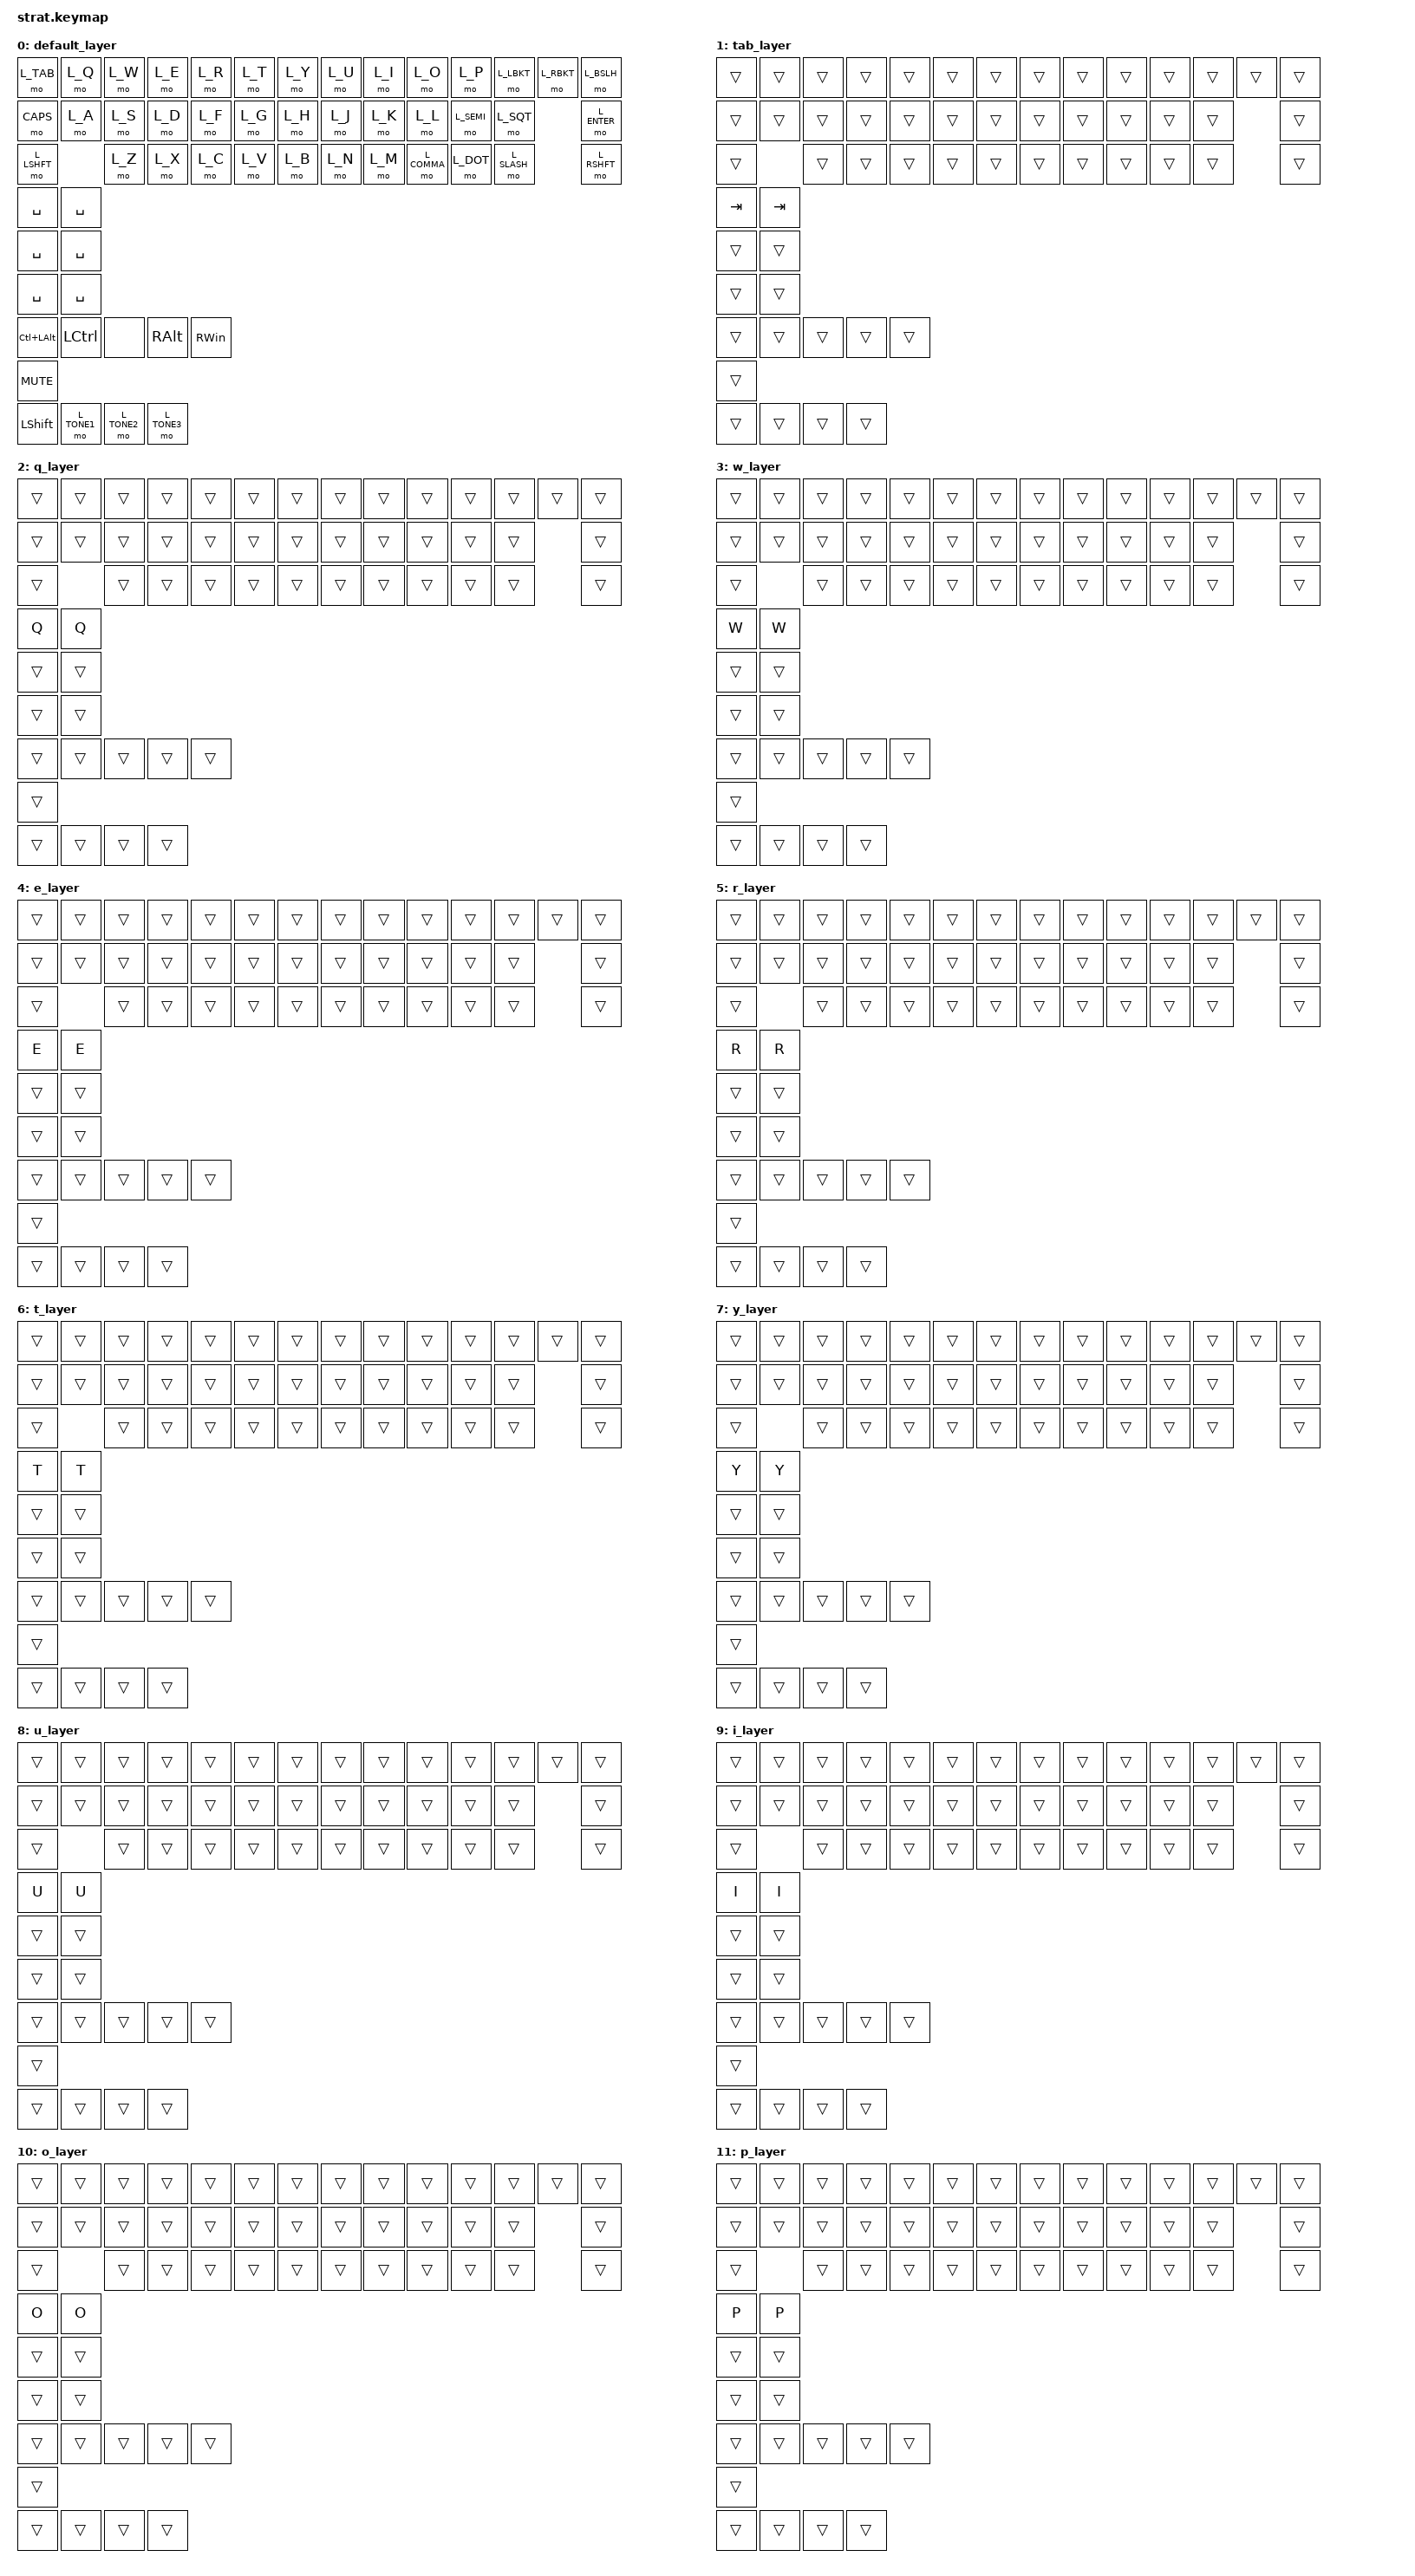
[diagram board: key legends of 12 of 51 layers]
#include <behaviors.dtsi>
#include <dt-bindings/zmk/keys.h>
#include <dt-bindings/zmk/bt.h>

#define DEFAULT    0

#define L_TAB     1
#define L_Q       2
#define L_W       3
#define L_E       4
#define L_R       5
#define L_T       6
#define L_Y       7
#define L_U       8
#define L_I       9
#define L_O       10
#define L_P       11
#define L_LBKT    12
#define L_RBKT    13
#define L_BSLH    14

#define L_CAPS    15
#define L_A       16
#define L_S       17
#define L_D       18
#define L_F       19
#define L_G       20
#define L_H       21
#define L_J       22
#define L_K       23
#define L_L       24
#define L_SEMI    25
#define L_SQT     26
#define L_ENTER   27

#define L_LSHFT   28
#define L_Z       29
#define L_X       30
#define L_C       31
#define L_V       32
#define L_B       33
#define L_N       34
#define L_M       35
#define L_COMMA   36
#define L_DOT     37
#define L_SLASH   38
#define L_RSHFT   39

#define L_PU0     40
#define L_PU1     41
#define L_PU2     42
#define L_PU3     43
#define L_PU4     44
#define L_TAB     45

#define L_TONE0   46
#define L_TONE1   47
#define L_TONE2   48
#define L_TONE3   49

#define L_CONFIG  50
#define L_NORMAL  51

/ {
    keymap {
        compatible = "zmk,keymap";

        // LAYER 0
        default_layer {
            bindings = <
                &mo L_TAB    &mo L_Q      &mo L_W      &mo L_E      &mo L_R      &mo L_T      &mo L_Y      &mo L_U      &mo L_I      &mo L_O      &mo L_P      &mo L_LBKT   &mo L_RBKT   &mo L_BSLH
                &mo CAPS     &mo L_A      &mo L_S      &mo L_D      &mo L_F      &mo L_G      &mo L_H      &mo L_J      &mo L_K      &mo L_L      &mo L_SEMI   &mo L_SQT                 &mo L_ENTER
                &mo L_LSHFT               &mo L_Z      &mo L_X      &mo L_C      &mo L_V      &mo L_B      &mo L_N      &mo L_M      &mo L_COMMA  &mo L_DOT    &mo L_SLASH               &mo L_RSHFT

                &kp SPACE    &kp SPACE
                &kp SPACE    &kp SPACE
                &kp SPACE    &kp SPACE

                &kp LC(LALT) &kp LCTRL    &none        &kp RALT     &kp RWIN
                &kp C_MUTE
                &kp LSHIFT   &mo L_TONE1  &mo L_TONE2  &mo L_TONE3
            >;
        };

        tab_layer {
            bindings = <
                &trans &trans &trans &trans &trans &trans &trans &trans &trans &trans &trans &trans &trans &trans &trans &trans &trans &trans &trans &trans &trans &trans &trans &trans &trans &trans &trans &trans &trans &trans &trans &trans &trans &trans &trans &trans &trans &trans &trans

                &kp TAB &kp TAB
                &trans &trans
                &trans &trans

                &trans &trans &trans &trans &trans &trans &trans &trans &trans &trans
            >;
        };

        q_layer {
            bindings = <
                &trans &trans &trans &trans &trans &trans &trans &trans &trans &trans &trans &trans &trans &trans &trans &trans &trans &trans &trans &trans &trans &trans &trans &trans &trans &trans &trans &trans &trans &trans &trans &trans &trans &trans &trans &trans &trans &trans &trans

                &kp Q &kp Q
                &trans &trans
                &trans &trans

                &trans &trans &trans &trans &trans &trans &trans &trans &trans &trans
            >;
        };

        w_layer {
            bindings = <
                &trans &trans &trans &trans &trans &trans &trans &trans &trans &trans &trans &trans &trans &trans &trans &trans &trans &trans &trans &trans &trans &trans &trans &trans &trans &trans &trans &trans &trans &trans &trans &trans &trans &trans &trans &trans &trans &trans &trans

                &kp W &kp W
                &trans &trans
                &trans &trans

                &trans &trans &trans &trans &trans &trans &trans &trans &trans &trans
            >;
        };

        e_layer {
            bindings = <
                &trans &trans &trans &trans &trans &trans &trans &trans &trans &trans &trans &trans &trans &trans &trans &trans &trans &trans &trans &trans &trans &trans &trans &trans &trans &trans &trans &trans &trans &trans &trans &trans &trans &trans &trans &trans &trans &trans &trans

                &kp E &kp E
                &trans &trans
                &trans &trans

                &trans &trans &trans &trans &trans &trans &trans &trans &trans &trans
            >;
        };

        r_layer {
            bindings = <
                &trans &trans &trans &trans &trans &trans &trans &trans &trans &trans &trans &trans &trans &trans &trans &trans &trans &trans &trans &trans &trans &trans &trans &trans &trans &trans &trans &trans &trans &trans &trans &trans &trans &trans &trans &trans &trans &trans &trans

                &kp R &kp R
                &trans &trans
                &trans &trans

                &trans &trans &trans &trans &trans &trans &trans &trans &trans &trans
            >;
        };

        t_layer {
            bindings = <
                &trans &trans &trans &trans &trans &trans &trans &trans &trans &trans &trans &trans &trans &trans &trans &trans &trans &trans &trans &trans &trans &trans &trans &trans &trans &trans &trans &trans &trans &trans &trans &trans &trans &trans &trans &trans &trans &trans &trans

                &kp T &kp T
                &trans &trans
                &trans &trans

                &trans &trans &trans &trans &trans &trans &trans &trans &trans &trans
            >;
        };

        y_layer {
            bindings = <
                &trans &trans &trans &trans &trans &trans &trans &trans &trans &trans &trans &trans &trans &trans &trans &trans &trans &trans &trans &trans &trans &trans &trans &trans &trans &trans &trans &trans &trans &trans &trans &trans &trans &trans &trans &trans &trans &trans &trans

                &kp Y &kp Y
                &trans &trans
                &trans &trans

                &trans &trans &trans &trans &trans &trans &trans &trans &trans &trans
            >;
        };

        u_layer {
            bindings = <
                &trans &trans &trans &trans &trans &trans &trans &trans &trans &trans &trans &trans &trans &trans &trans &trans &trans &trans &trans &trans &trans &trans &trans &trans &trans &trans &trans &trans &trans &trans &trans &trans &trans &trans &trans &trans &trans &trans &trans

                &kp U &kp U
                &trans &trans
                &trans &trans

                &trans &trans &trans &trans &trans &trans &trans &trans &trans &trans
            >;
        };

        i_layer {
            bindings = <
                &trans &trans &trans &trans &trans &trans &trans &trans &trans &trans &trans &trans &trans &trans &trans &trans &trans &trans &trans &trans &trans &trans &trans &trans &trans &trans &trans &trans &trans &trans &trans &trans &trans &trans &trans &trans &trans &trans &trans

                &kp I &kp I
                &trans &trans
                &trans &trans

                &trans &trans &trans &trans &trans &trans &trans &trans &trans &trans
            >;
        };

        // LAYER 10
        o_layer {
            bindings = <
                &trans &trans &trans &trans &trans &trans &trans &trans &trans &trans &trans &trans &trans &trans &trans &trans &trans &trans &trans &trans &trans &trans &trans &trans &trans &trans &trans &trans &trans &trans &trans &trans &trans &trans &trans &trans &trans &trans &trans

                &kp O &kp O
                &trans &trans
                &trans &trans

                &trans &trans &trans &trans &trans &trans &trans &trans &trans &trans
            >;
        };

        p_layer {
            bindings = <
                &trans &trans &trans &trans &trans &trans &trans &trans &trans &trans &trans &trans &trans &trans &trans &trans &trans &trans &trans &trans &trans &trans &trans &trans &trans &trans &trans &trans &trans &trans &trans &trans &trans &trans &trans &trans &trans &trans &trans

                &kp P &kp P
                &trans &trans
                &trans &trans

                &trans &trans &trans &trans &trans &trans &trans &trans &trans &trans
            >;
        };

        lbkt_layer {
            bindings = <
                &trans &trans &trans &trans &trans &trans &trans &trans &trans &trans &trans &trans &trans &trans &trans &trans &trans &trans &trans &trans &trans &trans &trans &trans &trans &trans &trans &trans &trans &trans &trans &trans &trans &trans &trans &trans &trans &trans &trans

                &kp LBKT &kp LBKT
                &trans &trans
                &trans &trans

                &trans &trans &trans &trans &trans &trans &trans &trans &trans &trans
            >;
        };

        rbkt_layer {
            bindings = <
                &trans &trans &trans &trans &trans &trans &trans &trans &trans &trans &trans &trans &trans &trans &trans &trans &trans &trans &trans &trans &trans &trans &trans &trans &trans &trans &trans &trans &trans &trans &trans &trans &trans &trans &trans &trans &trans &trans &trans

                &kp RBKT &kp RBKT
                &trans &trans
                &trans &trans

                &trans &trans &trans &trans &trans &trans &trans &trans &trans &trans
            >;
        };

        bslh_layer {
            bindings = <
                &trans &trans &trans &trans &trans &trans &trans &trans &trans &trans &trans &trans &trans &trans &trans &trans &trans &trans &trans &trans &trans &trans &trans &trans &trans &trans &trans &trans &trans &trans &trans &trans &trans &trans &trans &trans &trans &trans &trans

                &kp BSLH &kp BSLH
                &trans &trans
                &trans &trans

                &trans &trans &trans &trans &trans &trans &trans &trans &trans &trans
            >;
        };

        caps_layer {
            bindings = <
                &trans &trans &trans &trans &trans &trans &trans &trans &trans &trans &trans &trans &trans &trans &trans &trans &trans &trans &trans &trans &trans &trans &trans &trans &trans &trans &trans &trans &trans &trans &trans &trans &trans &trans &trans &trans &trans &trans &trans

                &trans &trans
                &kp CAPS &kp CAPS
                &trans &trans

                &trans &trans &trans &trans &trans &trans &trans &trans &trans &trans
            >;
        };

        a_layer {
            bindings = <
                &trans &trans &trans &trans &trans &trans &trans &trans &trans &trans &trans &trans &trans &trans &trans &trans &trans &trans &trans &trans &trans &trans &trans &trans &trans &trans &trans &trans &trans &trans &trans &trans &trans &trans &trans &trans &trans &trans &trans

                &trans &trans
                &kp A &kp A
                &trans &trans

                &trans &trans &trans &trans &trans &trans &trans &trans &trans &trans
            >;
        };

        s_layer {
            bindings = <
                &trans &trans &trans &trans &trans &trans &trans &trans &trans &trans &trans &trans &trans &trans &trans &trans &trans &trans &trans &trans &trans &trans &trans &trans &trans &trans &trans &trans &trans &trans &trans &trans &trans &trans &trans &trans &trans &trans &trans

                &trans &trans
                &kp S &kp S
                &trans &trans

                &trans &trans &trans &trans &trans &trans &trans &trans &trans &trans
            >;
        };

        d_layer {
            bindings = < &trans &trans &trans &trans &trans &trans &trans &trans &trans &trans &trans &trans &trans &trans &trans &trans &trans &trans &trans &trans &trans &trans &trans &trans &trans &trans &trans &trans &trans &trans &trans &trans &trans &trans &trans &trans &trans &trans &trans
                &trans &trans &kp D &kp D
                &trans &trans &trans &trans &trans &trans &trans &trans &trans &trans &trans &trans >;
        };

        f_layer {
            bindings = < &trans &trans &trans &trans &trans &trans &trans &trans &trans &trans &trans &trans &trans &trans &trans &trans &trans &trans &trans &trans &trans &trans &trans &trans &trans &trans &trans &trans &trans &trans &trans &trans &trans &trans &trans &trans &trans &trans &trans
                &trans &trans &kp F &kp F
                &trans &trans &trans &trans &trans &trans &trans &trans &trans &trans &trans &trans >;
        };

        g_layer {
            bindings = < &trans &trans &trans &trans &trans &trans &trans &trans &trans &trans &trans &trans &trans &trans &trans &trans &trans &trans &trans &trans &trans &trans &trans &trans &trans &trans &trans &trans &trans &trans &trans &trans &trans &trans &trans &trans &trans &trans &trans
                &trans &trans &kp G &kp G
                &trans &trans &trans &trans &trans &trans &trans &trans &trans &trans &trans &trans >;
        };

        h_layer {
            bindings = < &trans &trans &trans &trans &trans &trans &trans &trans &trans &trans &trans &trans &trans &trans &trans &trans &trans &trans &trans &trans &trans &trans &trans &trans &trans &trans &trans &trans &trans &trans &trans &trans &trans &trans &trans &trans &trans &trans &trans
                &trans &trans &kp H &kp H
                &trans &trans &trans &trans &trans &trans &trans &trans &trans &trans &trans &trans >;
        };

        j_layer {
            bindings = < &trans &trans &trans &trans &trans &trans &trans &trans &trans &trans &trans &trans &trans &trans &trans &trans &trans &trans &trans &trans &trans &trans &trans &trans &trans &trans &trans &trans &trans &trans &trans &trans &trans &trans &trans &trans &trans &trans &trans
                &trans &trans &kp J &kp J
                &trans &trans &trans &trans &trans &trans &trans &trans &trans &trans &trans &trans >;
        };

        k_layer {
            bindings = < &trans &trans &trans &trans &trans &trans &trans &trans &trans &trans &trans &trans &trans &trans &trans &trans &trans &trans &trans &trans &trans &trans &trans &trans &trans &trans &trans &trans &trans &trans &trans &trans &trans &trans &trans &trans &trans &trans &trans
                &trans &trans &kp K &kp K
                &trans &trans &trans &trans &trans &trans &trans &trans &trans &trans &trans &trans >;
        };

        l_layer {
            bindings = < &trans &trans &trans &trans &trans &trans &trans &trans &trans &trans &trans &trans &trans &trans &trans &trans &trans &trans &trans &trans &trans &trans &trans &trans &trans &trans &trans &trans &trans &trans &trans &trans &trans &trans &trans &trans &trans &trans &trans
                &trans &trans &kp L &kp L
                &trans &trans &trans &trans &trans &trans &trans &trans &trans &trans &trans &trans >;
        };

        semi_layer {
            bindings = < &trans &trans &trans &trans &trans &trans &trans &trans &trans &trans &trans &trans &trans &trans &trans &trans &trans &trans &trans &trans &trans &trans &trans &trans &trans &trans &trans &trans &trans &trans &trans &trans &trans &trans &trans &trans &trans &trans &trans
                &trans &trans &kp SEMI &kp SEMI
                &trans &trans &trans &trans &trans &trans &trans &trans &trans &trans &trans &trans >;
        };

        sqt_layer {
            bindings = < &trans &trans &trans &trans &trans &trans &trans &trans &trans &trans &trans &trans &trans &trans &trans &trans &trans &trans &trans &trans &trans &trans &trans &trans &trans &trans &trans &trans &trans &trans &trans &trans &trans &trans &trans &trans &trans &trans &trans
                &trans &trans &kp SQT &kp SQT
                &trans &trans &trans &trans &trans &trans &trans &trans &trans &trans &trans &trans >;
        };

        enter_layer {
            bindings = < &trans &trans &trans &trans &trans &trans &trans &trans &trans &trans &trans &trans &trans &trans &trans &trans &trans &trans &trans &trans &trans &trans &trans &trans &trans &trans &trans &trans &trans &trans &trans &trans &trans &trans &trans &trans &trans &trans &trans
                &trans &trans &kp ENTER &kp ENTER
                &trans &trans &trans &trans &trans &trans &trans &trans &trans &trans &trans &trans >;
        };

        lshft_layer {
            bindings = < &trans &trans &trans &trans &trans &trans &trans &trans &trans &trans &trans &trans &trans &trans &trans &trans &trans &trans &trans &trans &trans &trans &trans &trans &trans &trans &trans &trans &trans &trans &trans &trans &trans &trans &trans &trans &trans &trans &trans
                &trans &trans &trans &trans &kp LSHFT &kp LSHFT
                &trans &trans &trans &trans &trans &trans &trans &trans &trans &trans >;
        };

        z_layer {
            bindings = < &trans &trans &trans &trans &trans &trans &trans &trans &trans &trans &trans &trans &trans &trans &trans &trans &trans &trans &trans &trans &trans &trans &trans &trans &trans &trans &trans &trans &trans &trans &trans &trans &trans &trans &trans &trans &trans &trans &trans
                &trans &trans &trans &trans &kp Z &kp Z
                &trans &trans &trans &trans &trans &trans &trans &trans &trans &trans >;
        };

        x_layer {
            bindings = < &trans &trans &trans &trans &trans &trans &trans &trans &trans &trans &trans &trans &trans &trans &trans &trans &trans &trans &trans &trans &trans &trans &trans &trans &trans &trans &trans &trans &trans &trans &trans &trans &trans &trans &trans &trans &trans &trans &trans
                &trans &trans &trans &trans &kp X &kp X
                &trans &trans &trans &trans &trans &trans &trans &trans &trans &trans >;
        };

        c_layer {
            bindings = < &trans &trans &trans &trans &trans &trans &trans &trans &trans &trans &trans &trans &trans &trans &trans &trans &trans &trans &trans &trans &trans &trans &trans &trans &trans &trans &trans &trans &trans &trans &trans &trans &trans &trans &trans &trans &trans &trans &trans
                &trans &trans &trans &trans &kp C &kp C
                &trans &trans &trans &trans &trans &trans &trans &trans &trans &trans >;
        };

        v_layer {
            bindings = < &trans &trans &trans &trans &trans &trans &trans &trans &trans &trans &trans &trans &trans &trans &trans &trans &trans &trans &trans &trans &trans &trans &trans &trans &trans &trans &trans &trans &trans &trans &trans &trans &trans &trans &trans &trans &trans &trans &trans
                &trans &trans &trans &trans &kp V &kp V
                &trans &trans &trans &trans &trans &trans &trans &trans &trans &trans >;
        };

        b_layer {
            bindings = < &trans &trans &trans &trans &trans &trans &trans &trans &trans &trans &trans &trans &trans &trans &trans &trans &trans &trans &trans &trans &trans &trans &trans &trans &trans &trans &trans &trans &trans &trans &trans &trans &trans &trans &trans &trans &trans &trans &trans
                &trans &trans &trans &trans &kp B &kp B
                &trans &trans &trans &trans &trans &trans &trans &trans &trans &trans >;
        };

        n_layer {
            bindings = < &trans &trans &trans &trans &trans &trans &trans &trans &trans &trans &trans &trans &trans &trans &trans &trans &trans &trans &trans &trans &trans &trans &trans &trans &trans &trans &trans &trans &trans &trans &trans &trans &trans &trans &trans &trans &trans &trans &trans
                &trans &trans &trans &trans &kp N &kp N
                &trans &trans &trans &trans &trans &trans &trans &trans &trans &trans >;
        };

        m_layer {
            bindings = < &trans &trans &trans &trans &trans &trans &trans &trans &trans &trans &trans &trans &trans &trans &trans &trans &trans &trans &trans &trans &trans &trans &trans &trans &trans &trans &trans &trans &trans &trans &trans &trans &trans &trans &trans &trans &trans &trans &trans
                &trans &trans &trans &trans &kp M &kp M
                &trans &trans &trans &trans &trans &trans &trans &trans &trans &trans >;
        };

        comma_layer {
            bindings = < &trans &trans &trans &trans &trans &trans &trans &trans &trans &trans &trans &trans &trans &trans &trans &trans &trans &trans &trans &trans &trans &trans &trans &trans &trans &trans &trans &trans &trans &trans &trans &trans &trans &trans &trans &trans &trans &trans &trans
                &trans &trans &trans &trans &kp COMMA &kp COMMA
                &trans &trans &trans &trans &trans &trans &trans &trans &trans &trans >;
        };

        dot_layer {
            bindings = < &trans &trans &trans &trans &trans &trans &trans &trans &trans &trans &trans &trans &trans &trans &trans &trans &trans &trans &trans &trans &trans &trans &trans &trans &trans &trans &trans &trans &trans &trans &trans &trans &trans &trans &trans &trans &trans &trans &trans
                &trans &trans &trans &trans &kp DOT &kp DOT
                &trans &trans &trans &trans &trans &trans &trans &trans &trans &trans >;
        };

        slash_layer {
            bindings = < &trans &trans &trans &trans &trans &trans &trans &trans &trans &trans &trans &trans &trans &trans &trans &trans &trans &trans &trans &trans &trans &trans &trans &trans &trans &trans &trans &trans &trans &trans &trans &trans &trans &trans &trans &trans &trans &trans &trans
                &trans &trans &trans &trans &kp SLASH &kp SLASH
                &trans &trans &trans &trans &trans &trans &trans &trans &trans &trans >;
        };

        rshft_layer {
            bindings = < &trans &trans &trans &trans &trans &trans &trans &trans &trans &trans &trans &trans &trans &trans &trans &trans &trans &trans &trans &trans &trans &trans &trans &trans &trans &trans &trans &trans &trans &trans &trans &trans &trans &trans &trans &trans &trans &trans &trans
                &trans &trans &trans &trans &kp RSHFT &kp RSHFT
                &trans &trans &trans &trans &trans &trans &trans &trans &trans &trans >;
        };

        pickup0_layer {
            bindings = <
                &trans &trans &trans &trans &trans &trans &trans &trans &trans &trans &trans &trans &trans &trans
                &trans &trans &trans &trans &trans &trans &trans &trans &trans &trans &trans &trans &trans
                &trans &trans &trans &trans &trans &trans &trans &trans &trans &trans &trans &trans

                &trans &trans
                &trans &trans
                &trans &trans

                &trans &trans &trans &trans &trans
                &trans
                &trans &trans &trans &trans
            >;
        };

        pickup1_layer {
            bindings = <
                &trans &trans &trans &trans &trans &trans &trans &trans &trans &trans &trans &trans &trans &trans
                &trans &trans &trans &trans &trans &trans &trans &trans &trans &trans &trans &trans &trans
                &trans &trans &trans &trans &trans &trans &trans &trans &trans &trans &trans &trans

                &trans &trans
                &trans &trans
                &trans &trans

                &trans &trans &trans &trans &trans
                &trans
                &trans &trans &trans &trans
            >;
        };

        pickup2_layer {
            bindings = <
                &trans &trans &trans &trans &trans &trans &trans &trans &trans &trans &trans &trans &trans &trans
                &trans &trans &trans &trans &trans &trans &trans &trans &trans &trans &trans &trans &trans
                &trans &trans &trans &trans &trans &trans &trans &trans &trans &trans &trans &trans

                &trans &trans
                &trans &trans
                &trans &trans

                &trans &trans &trans &trans &trans
                &trans
                &trans &trans &trans &trans
            >;
        };

        pickup3_layer {
            bindings = <
                &trans &trans &trans &trans &trans &trans &trans &trans &trans &trans &trans &trans &trans &trans
                &trans &trans &trans &trans &trans &trans &trans &trans &trans &trans &trans &trans &trans
                &trans &trans &trans &trans &trans &trans &trans &trans &trans &trans &trans &trans

                &trans &trans
                &trans &trans
                &trans &trans

                &trans &trans &trans &trans &trans
                &trans
                &trans &trans &trans &trans
            >;
        };

        pickup4_layer {
            bindings = <
                &trans &trans &trans &trans &trans &trans &trans &trans &trans &trans &trans &trans &trans &trans
                &trans &trans &trans &trans &trans &trans &trans &trans &trans &trans &trans &trans &trans
                &trans &trans &trans &trans &trans &trans &trans &trans &trans &trans &trans &trans

                &trans &trans
                &trans &trans
                &trans &trans

                &trans &trans &trans &trans &trans
                &trans
                &trans &trans &trans &trans
            >;
        };




        tone0_layer {
            bindings = <
                &trans &trans &trans &trans &trans &trans &trans &trans &trans &trans &trans &trans &trans &trans
                &trans &trans &trans &trans &trans &trans &trans &trans &trans &trans &trans &trans &trans
                &trans &trans &trans &trans &trans &trans &trans &trans &trans &trans &trans &trans

                &trans &trans
                &trans &trans
                &trans &trans

                &trans &trans &trans &trans &trans
                &trans
                &trans &trans &trans &trans
            >;
        };

        tone1_layer {
            bindings = <
                &trans &trans &trans &trans &trans &trans &trans &trans &trans &trans &trans &trans &trans &trans
                &trans &trans &trans &trans &trans &trans &trans &trans &trans &trans &trans &trans &trans
                &trans &trans &trans &trans &trans &trans &trans &trans &trans &trans &trans &trans

                &trans &trans
                &trans &trans
                &trans &trans

                &trans &trans &trans &trans &trans
                &trans
                &trans &trans &trans &trans
            >;
        };

        tone2_layer {
            bindings = <
                &trans &trans &trans &trans &trans &trans &trans &trans &trans &trans &trans &trans &trans &trans
                &trans &trans &trans &trans &trans &trans &trans &trans &trans &trans &trans &trans &trans
                &trans &trans &trans &trans &trans &trans &trans &trans &trans &trans &trans &trans

                &trans &trans
                &trans &trans
                &trans &trans

                &trans &trans &trans &trans &trans
                &trans
                &trans &trans &trans &trans
            >;
        };

        tone3_layer {
            bindings = <
                &none &none &none &none &none &none &none &none &none &none &none &none &none &none
                &none &none &none &none &none &none &none &none &none &none &none &none &none
                &mo L_CONFIG &none &none &none &none &none &none &none &none &none &none &none

                &none &none
                &none &none
                &none &none

                &none &none &none &none &none
                &none
                &none &none &none &none
            >;
        };

        // LAYER 50
        config_layer {
            bindings = <
                &none &none &none &none &none &none &none &none &none &none &none &none &none &none
                &none &none &none &none &none &none &none &none &none &none &none &none &none
                &none &none &none &none &none &none &none &none &none &none &none &to L_NORMAL

                &bt BT_NXT &bt BT_PRV
                &bt BT_NXT &bt BT_PRV
                &bt BT_NXT &bt BT_PRV

                &none &none &none &none &none
                &bt BT_CLR
                &none &none &none &none
            >;
        };

        normal_layer {
            bindings = <
                &kp L_TAB    &kp L_Q      &kp L_W      &kp L_E      &kp L_R      &kp L_T      &kp L_Y      &kp L_U      &kp L_I      &kp L_O      &kp L_P      &kp L_LBKT   &kp L_RBKT   &kp L_BSLH
                &kp CAPS     &kp L_A      &kp L_S      &kp L_D      &kp L_F      &kp L_G      &kp L_H      &kp L_J      &kp L_K      &kp L_L      &kp L_SEMI   &kp L_SQT                 &kp L_ENTER
                &kp L_LSHFT               &kp L_Z      &kp L_X      &kp L_C      &kp L_V      &kp L_B      &kp L_N      &kp L_M      &kp L_COMMA  &kp L_DOT    &kp L_SLASH               &trans

                &kp SPACE    &kp SPACE
                &kp SPACE    &kp SPACE
                &kp SPACE    &kp SPACE

                &trans &trans &trans &trans &trans
                &trans
                &trans &trans &trans &trans &trans
            >;
        };

    };
 };
